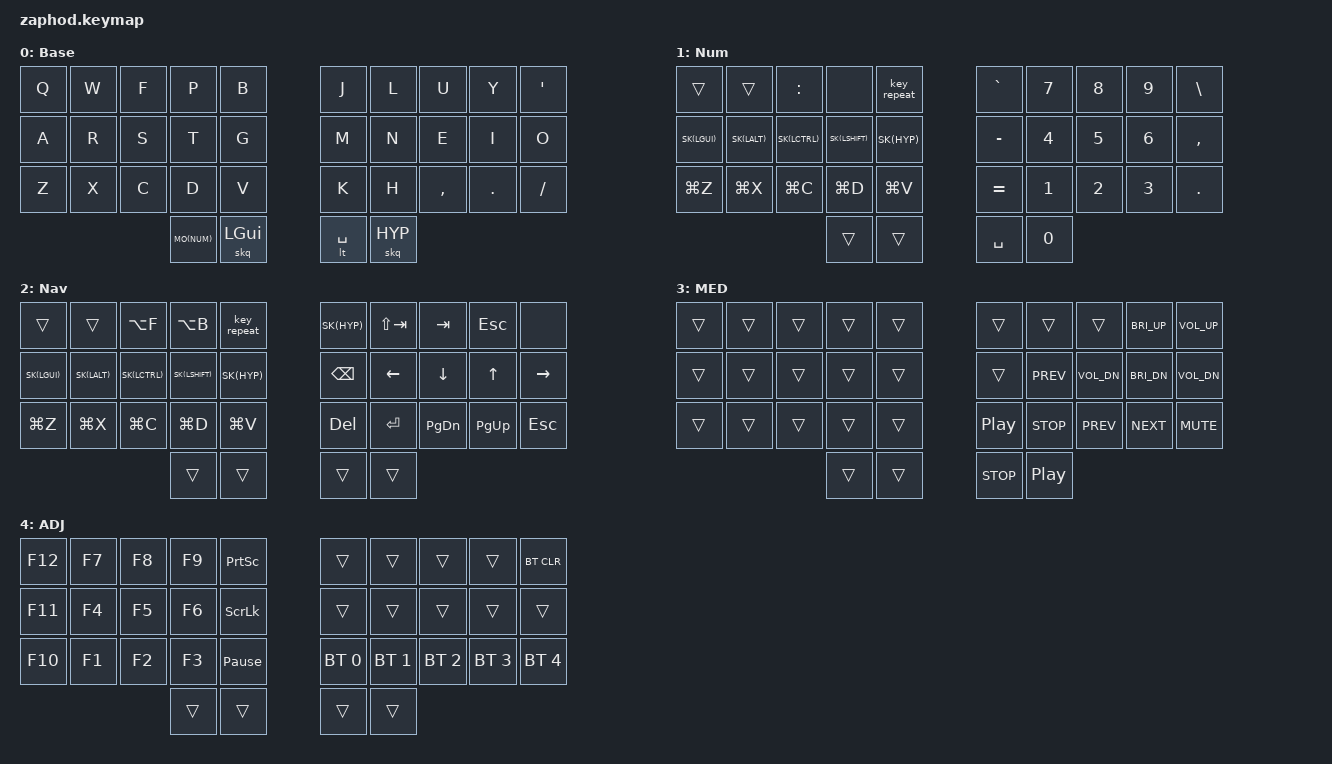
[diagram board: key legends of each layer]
/*
 * Copyright (c) 2021 Pete Johanson
 *
 * SPDX-License-Identifier: MIT
 */

#include <behaviors.dtsi>
#include <dt-bindings/zmk/keys.h>
#include <dt-bindings/zmk/bt.h>
#include <dt-bindings/zmk/outputs.h>
// #include "34keys.h"

#define BASE 0
#define NUM  1
#define NAV  2
#define MED  3
#define ADJ  4

#define XXX &none
#define ___ &trans

#define SK(KEY) &nk KEY KEY
#define MO(LAYER) &mo_tap LAYER F24
#define HYP LS(LC(LA(LGUI)))

// Using layer taps on thumbs, having quick tap as well helps w/ repeating space/backspace
// &lt { quick_tap_ms = <200>; };

// Sticky keys timeout after 1.5 seconds
#define STICKY_KEY_TIMEOUT 1500

&sk {
  release-after-ms = <STICKY_KEY_TIMEOUT>;
};

&lt {
  retro-tap;
  tapping_term_ms = <100>;
};

&kscan {
  debounce-period = <14>;
};

#define BT(n) BT_SEL n

/ {

    combos {
        #include "combos.dtsi"
    };
    // macros {
    //     #include "macros.dtsi"
    // };

    behaviors {
        skq: sticky_key_quick_release {
            compatible = "zmk,behavior-sticky-key";
            label = "STICKY_KEY_QUICK_RELEASE";
            #binding-cells = <1>;
            bindings = <&kp>;
            quick-release;
            release-after-ms = <STICKY_KEY_TIMEOUT>;
        };

        // Sticky key on tap, normal key on hold
        // Useful for modifier-clicking without the modifier remaining active
        nk: not_so_sticky_key {
            compatible = "zmk,behavior-hold-tap";
            label = "NOT_SO_STICKY_KEY";
            #binding-cells = <2>;
            tapping_term_ms = <200>;
            flavor = "tap-preferred";
            bindings = <&kp>, <&sk>;
        };

        // A hold-tap that activates without delay (like `&mo`)
        mo_tap: mo_with_tap {
            compatible = "zmk,behavior-hold-tap";
            label = "MO_WITH_TAP";
            #binding-cells = <2>;
            tapping_term_ms = <0>;
            retro-tap;
            flavor = "hold-preferred";
            bindings = <&mo>, <&kp>;
        };
    };

    keymap {
        compatible = "zmk,keymap";

        base_layer {
            display-name = "Base";
            bindings = <
// ┏━━━━━━━━━━━┳━━━━━━━━━━━┳━━━━━━━━━━━┳━━━━━━━━━━━┳━━━━━━━━━━━┓┏━━━━━━━━━━━┳━━━━━━━━━━━┳━━━━━━━━━━━┳━━━━━━━━━━━┳━━━━━━━━━━━┓
    &kp Q       &kp W       &kp F       &kp P       &kp B        &kp J       &kp L       &kp U       &kp Y       &kp APOS
// ┣━━━━━━━━━━━╋━━━━━━━━━━━╋━━━━━━━━━━━╋━━━━━━━━━━━╋━━━━━━━━━━━┫┣━━━━━━━━━━━╋━━━━━━━━━━━╋━━━━━━━━━━━╋━━━━━━━━━━━╋━━━━━━━━━━━┫
    &kp A       &kp R       &kp S       &kp T       &kp G        &kp M       &kp N       &kp E       &kp I       &kp O
// ┣━━━━━━━━━━━╋━━━━━━━━━━━╋━━━━━━━━━━━╋━━━━━━━━━━━╋━━━━━━━━━━━┫┣━━━━━━━━━━━╋━━━━━━━━━━━╋━━━━━━━━━━━╋━━━━━━━━━━━╋━━━━━━━━━━━┫
    &kp Z       &kp X       &kp C       &kp D       &kp V        &kp K       &kp H       &kp COMMA   &kp DOT     &kp FSLH
// ┗━━━━━━━━━━━┻━━━━━━━━━━━╋━━━━━━━━━━━╋━━━━━━━━━━━╋━━━━━━━━━━━┫┣━━━━━━━━━━━╋━━━━━━━━━━━╋━━━━━━━━━━━╋━━━━━━━━━━━┻━━━━━━━━━━━┛
                                        MO(NUM)      &skq LGUI   &lt SPACE   &skq HYP
//                                     ┗━━━━━━━━━━━┻━━━━━━━━━━━┛┗━━━━━━━━━━━┻━━━━━━━━━━━┛
            >;
        };

        num_layer {
            display-name = "Num";
            bindings = <
// ┏━━━━━━━━━━━┳━━━━━━━━━━━┳━━━━━━━━━━━┳━━━━━━━━━━━┳━━━━━━━━━━━┓┏━━━━━━━━━━━┳━━━━━━━━━━━┳━━━━━━━━━━━┳━━━━━━━━━━━┳━━━━━━━━━━━┓
    ___         ___         &kp COLON   XXX         &key_repeat  &kp GRAVE   &kp N7      &kp N8      &kp N9      &kp BSLH
// ┣━━━━━━━━━━━╋━━━━━━━━━━━╋━━━━━━━━━━━╋━━━━━━━━━━━╋━━━━━━━━━━━┫┣━━━━━━━━━━━╋━━━━━━━━━━━╋━━━━━━━━━━━╋━━━━━━━━━━━╋━━━━━━━━━━━┫
    SK(LGUI)    SK(LALT)    SK(LCTRL)   SK(LSHIFT)  SK(HYP)      &kp MINUS   &kp N4      &kp N5      &kp N6      &kp COMMA
// ┣━━━━━━━━━━━╋━━━━━━━━━━━╋━━━━━━━━━━━╋━━━━━━━━━━━╋━━━━━━━━━━━┫┣━━━━━━━━━━━╋━━━━━━━━━━━╋━━━━━━━━━━━╋━━━━━━━━━━━╋━━━━━━━━━━━┫
    &kp LG(Z)   &kp LG(X)   &kp LG(C)   &kp LG(D)   &kp LG(V)    &kp EQUAL   &kp N1      &kp N2      &kp N3      &kp DOT
// ┗━━━━━━━━━━━┻━━━━━━━━━━━╋━━━━━━━━━━━╋━━━━━━━━━━━╋━━━━━━━━━━━┫┣━━━━━━━━━━━╋━━━━━━━━━━━╋━━━━━━━━━━━╋━━━━━━━━━━━┻━━━━━━━━━━━┛
                                        ___         ___          &kp SPACE   &kp N0
//                                     ┗━━━━━━━━━━━┻━━━━━━━━━━━┛┗━━━━━━━━━━━┻━━━━━━━━━━━┛
            >;
        };

        nav_layer {
            display-name = "Nav";
            bindings = <
// ┏━━━━━━━━━━━┳━━━━━━━━━━━┳━━━━━━━━━━━┳━━━━━━━━━━━┳━━━━━━━━━━━┓┏━━━━━━━━━━━┳━━━━━━━━━━━┳━━━━━━━━━━━┳━━━━━━━━━━━┳━━━━━━━━━━━┓
    ___         ___         &kp LA(F)   &kp LA(B)   &key_repeat  SK(HYP)     &kp LS(TAB) &kp TAB     &kp ESC     XXX
// ┣━━━━━━━━━━━╋━━━━━━━━━━━╋━━━━━━━━━━━╋━━━━━━━━━━━╋━━━━━━━━━━━┫┣━━━━━━━━━━━╋━━━━━━━━━━━╋━━━━━━━━━━━╋━━━━━━━━━━━╋━━━━━━━━━━━┫
    SK(LGUI)    SK(LALT)    SK(LCTRL)   SK(LSHIFT)  SK(HYP)      &kp BSPC    &kp LEFT    &kp DOWN    &kp UP      &kp RIGHT
// ┣━━━━━━━━━━━╋━━━━━━━━━━━╋━━━━━━━━━━━╋━━━━━━━━━━━╋━━━━━━━━━━━┫┣━━━━━━━━━━━╋━━━━━━━━━━━╋━━━━━━━━━━━╋━━━━━━━━━━━╋━━━━━━━━━━━┫
    &kp LG(Z)   &kp LG(X)   &kp LG(C)   &kp LG(D)   &kp LG(V)    &kp DEL     &kp ENTER   &kp PG_DN   &kp PG_UP   &kp ESC
// ┗━━━━━━━━━━━┻━━━━━━━━━━━╋━━━━━━━━━━━╋━━━━━━━━━━━╋━━━━━━━━━━━┫┣━━━━━━━━━━━╋━━━━━━━━━━━╋━━━━━━━━━━━╋━━━━━━━━━━━┻━━━━━━━━━━━┛
                                        &trans      &trans       &trans      &trans
//                                     ┗━━━━━━━━━━━┻━━━━━━━━━━━┛┗━━━━━━━━━━━┻━━━━━━━━━━━┛
            >;
        };

        media_layer {
            display-name = "MED";
            bindings = <
// ┏━━━━━━━━━━━┳━━━━━━━━━━━┳━━━━━━━━━━━┳━━━━━━━━━━━┳━━━━━━━━━━━┓┏━━━━━━━━━━━┳━━━━━━━━━━━┳━━━━━━━━━━━┳━━━━━━━━━━━┳━━━━━━━━━━━┓
    &trans      &trans      &trans      &trans      &trans       &trans      &trans      &trans      &kp C_BRI_UP &kp C_VOL_UP
    &trans      &trans      &trans      &trans      &trans       &trans      &kp C_PREV &kp C_VOL_DN &kp C_BRI_DN &kp C_VOL_DN
    &trans      &trans      &trans      &trans      &trans       &kp C_PP    &kp C_STOP  &kp C_PREV  &kp C_NEXT   &kp C_MUTE
// ┗━━━━━━━━━━━┻━━━━━━━━━━━╋━━━━━━━━━━━╋━━━━━━━━━━━╋━━━━━━━━━━━┫┣━━━━━━━━━━━╋━━━━━━━━━━━╋━━━━━━━━━━━╋━━━━━━━━━━━┻━━━━━━━━━━━┛
                                        &trans      &trans       &kp C_STOP  &kp C_PLAY_PAUSE
//                                     ┗━━━━━━━━━━━┻━━━━━━━━━━━┛┗━━━━━━━━━━━┻━━━━━━━━━━━┛
            >;
        };

        adjust_layer {
            display-name = "ADJ";
            bindings = <
// ┏━━━━━━━━━━━┳━━━━━━━━━━━┳━━━━━━━━━━━┳━━━━━━━━━━━┳━━━━━━━━━━━┓┏━━━━━━━━━━━┳━━━━━━━━━━━┳━━━━━━━━━━━┳━━━━━━━━━━━┳━━━━━━━━━━━┓
    &kp F12    &kp F7     &kp F8    &kp F9    &kp PSCRN         &trans          &trans          &trans       &trans       &bt BT_CLR
    &kp F11    &kp F4     &kp F5    &kp F6    &kp SLCK          &trans          &trans          &trans       &trans       &trans
    &kp F10    &kp F1     &kp F2    &kp F3    &kp PAUSE_BREAK   &bt BT_SEL 0    &bt BT_SEL 1    &bt BT_SEL 2 &bt BT_SEL 3 &bt BT_SEL 4
// ┗━━━━━━━━━━━┻━━━━━━━━━━━╋━━━━━━━━━━━╋━━━━━━━━━━━╋━━━━━━━━━━━┫┣━━━━━━━━━━━╋━━━━━━━━━━━╋━━━━━━━━━━━╋━━━━━━━━━━━┻━━━━━━━━━━━┛
                                    &trans    &trans            &trans     &trans
//                                     ┗━━━━━━━━━━━┻━━━━━━━━━━━┛┗━━━━━━━━━━━┻━━━━━━━━━━━┛
            >;
        };
    };
};

